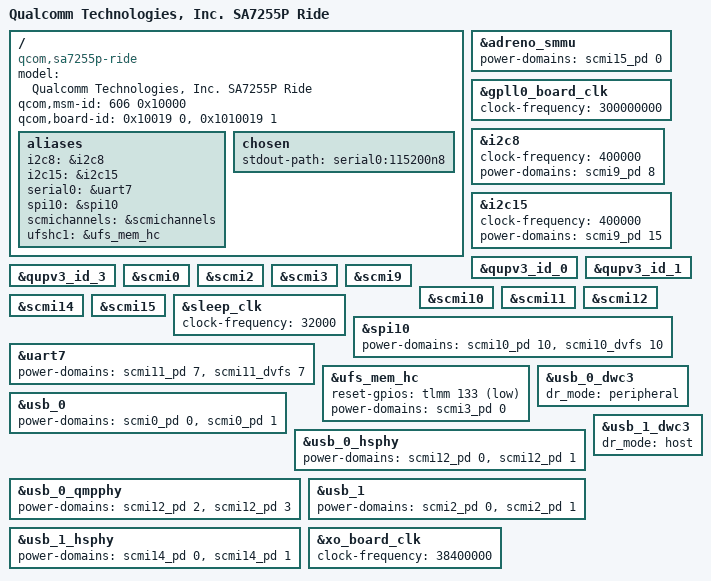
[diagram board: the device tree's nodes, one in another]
// SPDX-License-Identifier: BSD-3-Clause
/*
 * Copyright (c) 2024 Qualcomm Innovation Center, Inc. All rights reserved.
 */

/dts-v1/;

#include <dt-bindings/gpio/gpio.h>

#include "sa7255p.dtsi"
#include "sa7255p-scmi.dtsi"

/ {
	model = "Qualcomm Technologies, Inc. SA7255P Ride";
	compatible = "qcom,sa7255p-ride","qcom,sa7255p";
	qcom,msm-id = <606 0x10000>;
	qcom,board-id = <0x10019 0>, <0x1010019 1>;

	aliases {
		i2c8 = &i2c8;
		i2c15 = &i2c15;
		serial0 = &uart7;
		spi10 = &spi10;
		scmichannels = &scmichannels;
		ufshc1 = &ufs_mem_hc;
	};

	chosen {
		stdout-path = "serial0:115200n8";
	};
};

&adreno_smmu {
	power-domains = <&scmi15_pd 0>;

	status = "okay";
};

&gpll0_board_clk {
	clock-frequency = <300000000>;
};

&i2c8 {
	clock-frequency = <400000>;
	power-domains = <&scmi9_pd 8>;

	status = "okay";
};

&i2c15 {
	clock-frequency = <400000>;
	power-domains = <&scmi9_pd 15>;

	status = "okay";
};

&qupv3_id_0 {
	status = "okay";
};

&qupv3_id_1 {
	status = "okay";
};

&qupv3_id_3 {
	status = "okay";
};

&scmi0 {
	status = "okay";
};

&scmi2 {
	status = "okay";
};

&scmi3 {
	status = "okay";
};

&scmi9 {
	status = "okay";
};

&scmi10 {
	status = "okay";
};

&scmi11 {
	status = "okay";
};

&scmi12 {
	status = "okay";
};

&scmi14 {
	status = "okay";
};

&scmi15 {
	status = "okay";
};

&sleep_clk {
	clock-frequency = <32000>;
};

&spi10 {
	power-domains = <&scmi10_pd 10>, <&scmi10_dvfs 10>;
	power-domain-names = "power", "perf";

	status = "okay";
};

&uart7 {
	power-domains = <&scmi11_pd 7>, <&scmi11_dvfs 7>;
	power-domain-names = "power", "perf";

	status = "okay";
};

&ufs_mem_hc {
	reset-gpios = <&tlmm 133 GPIO_ACTIVE_LOW>;
	power-domains = <&scmi3_pd 0>;

	status = "okay";
};

&usb_0 {
	power-domains = <&scmi0_pd 0>, <&scmi0_pd 1>;
	power-domain-names = "usb_transfer", "usb_core";

	status = "okay";
};

&usb_0_dwc3 {
	dr_mode = "peripheral";
};

&usb_0_hsphy {
	power-domains = <&scmi12_pd 0>, <&scmi12_pd 1>;
	power-domain-names = "usb_transfer", "usb_core";

	status = "okay";
};

&usb_0_qmpphy {
	power-domains = <&scmi12_pd 2>, <&scmi12_pd 3>;
	power-domain-names = "usb_transfer", "usb_core";

	status = "okay";
};

&usb_1 {
	power-domains = <&scmi2_pd 0>, <&scmi2_pd 1>;
	power-domain-names = "usb_transfer", "usb_core";

	status = "okay";
};

&usb_1_dwc3 {
	dr_mode = "host";
};

&usb_1_hsphy {
	power-domains = <&scmi14_pd 0>, <&scmi14_pd 1>;
	power-domain-names = "usb_transfer", "usb_core";

	status = "okay";
};

&xo_board_clk {
	clock-frequency = <38400000>;
};
